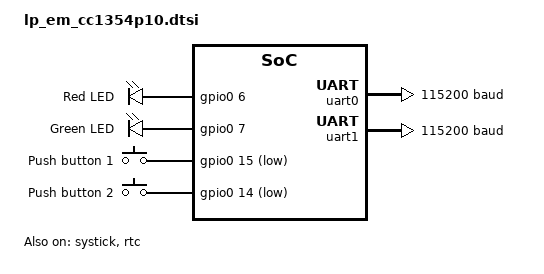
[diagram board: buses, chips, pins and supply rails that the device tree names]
/*
 * Copyright (c) 2026 Texas Instruments Incorporated
 *
 * SPDX-License-Identifier: Apache-2.0
 */

#include <ti/cc1354p10.dtsi>
#include "lp_em_cc1354p10-pinctrl.dtsi"
#include <zephyr/dt-bindings/input/input-event-codes.h>

/ {
	aliases {
		led0 = &led0;
		led1 = &led1;
		sw0 = &btn0;
		sw1 = &btn1;
	};

	chosen {
		zephyr,sram = &sram0;
		zephyr,flash = &flash0;
		zephyr,console = &uart0;
		zephyr,shell-uart = &uart0;
		zephyr,code-partition = &slot0_partition;
	};

	leds {
		compatible = "gpio-leds";

		led0: led_0 {
			gpios = <&gpio0 6 GPIO_ACTIVE_HIGH>;
			label = "Red LED";
		};

		led1: led_1 {
			gpios = <&gpio0 7 GPIO_ACTIVE_HIGH>;
			label = "Green LED";
		};
	};

	keys {
		compatible = "gpio-keys";

		btn0: btn_0 {
			gpios = <&gpio0 15 (GPIO_ACTIVE_LOW | GPIO_PULL_UP)>;
			label = "Push button 1";
			zephyr,code = <INPUT_KEY_0>;
		};

		btn1: btn_1 {
			gpios = <&gpio0 14 (GPIO_ACTIVE_LOW | GPIO_PULL_UP)>;
			label = "Push button 2";
			zephyr,code = <INPUT_KEY_1>;
		};
	};
};

&flash0 {
	partitions {
		compatible = "fixed-partitions";
		#address-cells = <1>;
		#size-cells = <1>;

		boot_partition: partition@0 {
			label = "mcuboot";
			reg = <0x00000000 0x0000a000>;
		};

		slot0_partition: partition@a000 {
			label = "image-0";
			reg = <0x0000a000 0x00076000>;
		};

		slot1_partition: partition@80000 {
			label = "image-1";
			reg = <0x00080000 0x00076000>;
		};

		storage_partition: partition@f6000 {
			label = "storage";
			reg = <0x000f6000 0x0000a000>;
		};
	};
};

&cpu0 {
	clock-frequency = <48000000>;
};

&gpio0 {
	status = "okay";
};

&uart0 {
	status = "okay";
	current-speed = <115200>;
	pinctrl-0 = <&uart0_rx_default &uart0_tx_default>;
	pinctrl-names = "default";
};

&spi0 {
	status = "disabled";
	pinctrl-0 = <&spi0_sck_default &spi0_mosi_default &spi0_miso_default>;
	pinctrl-names = "default";
	cs-gpios = <&gpio0 9 GPIO_ACTIVE_LOW>;
};

&adc0 {
	status = "disabled";
	pinctrl-0 = <&adc0_default>;
	pinctrl-names = "default";
};

&uart1 {
	status = "okay";
	current-speed = <115200>;
	pinctrl-0 = <&uart1_rx_default &uart1_tx_default>;
	pinctrl-names = "default";
};

&systick {
	status = "okay";
};

&dma0 {
	status = "disabled";
};

&rtc {
	status = "okay";
};
